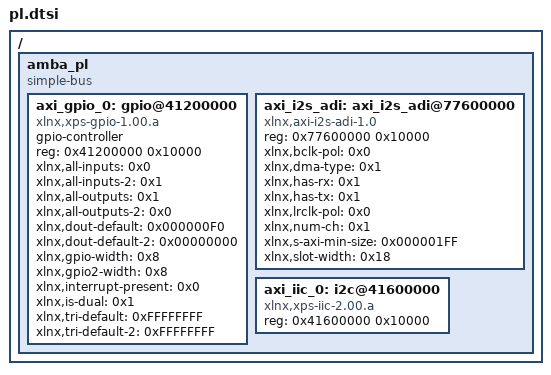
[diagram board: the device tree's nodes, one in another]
/*
 * CAUTION: This file is automatically generated by Xilinx.
 * Version:  
 * Today is: Sat Oct  3 00:42:54 2015
*/


/ {
	amba_pl: amba_pl {
		#address-cells = <1>;
		#size-cells = <1>;
		compatible = "simple-bus";
		ranges ;
		axi_gpio_0: gpio@41200000 {
			#gpio-cells = <2>;
			compatible = "xlnx,xps-gpio-1.00.a";
			gpio-controller ;
			reg = <0x41200000 0x10000>;
			xlnx,all-inputs = <0x0>;
			xlnx,all-inputs-2 = <0x1>;
			xlnx,all-outputs = <0x1>;
			xlnx,all-outputs-2 = <0x0>;
			xlnx,dout-default = <0x000000F0>;
			xlnx,dout-default-2 = <0x00000000>;
			xlnx,gpio-width = <0x8>;
			xlnx,gpio2-width = <0x8>;
			xlnx,interrupt-present = <0x0>;
			xlnx,is-dual = <0x1>;
			xlnx,tri-default = <0xFFFFFFFF>;
			xlnx,tri-default-2 = <0xFFFFFFFF>;
		};
		axi_i2s_adi: axi_i2s_adi@77600000 {
			compatible = "xlnx,axi-i2s-adi-1.0";
			reg = <0x77600000 0x10000>;
			xlnx,bclk-pol = <0x0>;
			xlnx,dma-type = <0x1>;
			xlnx,has-rx = <0x1>;
			xlnx,has-tx = <0x1>;
			xlnx,lrclk-pol = <0x0>;
			xlnx,num-ch = <0x1>;
			xlnx,s-axi-min-size = <0x000001FF>;
			xlnx,slot-width = <0x18>;
		};
		axi_iic_0: i2c@41600000 {
			#address-cells = <1>;
			#size-cells = <0>;
			compatible = "xlnx,xps-iic-2.00.a";
			reg = <0x41600000 0x10000>;
		};
	};
};
